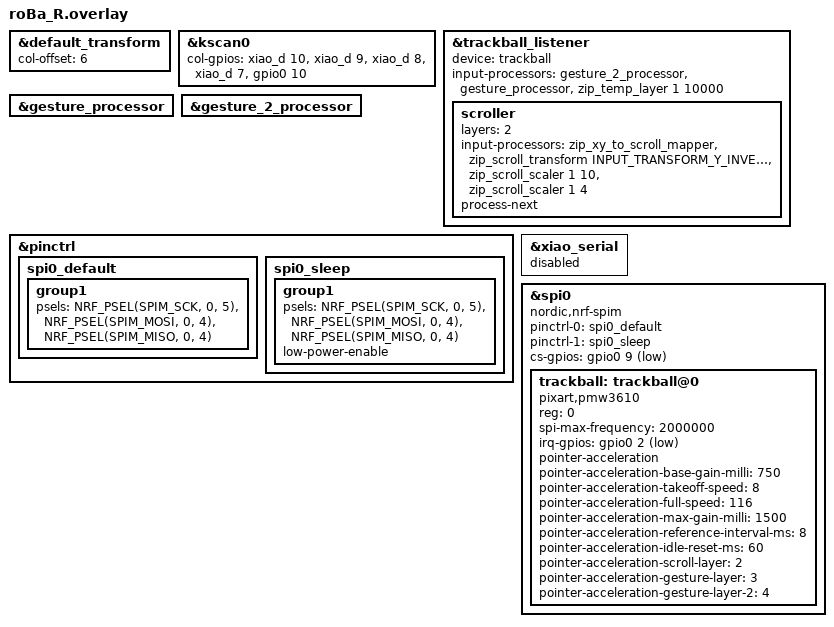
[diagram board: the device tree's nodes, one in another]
#include "roBa.dtsi"
#include <dt-bindings/zmk/input_transform.h>

&default_transform {
    col-offset = <6>;
};

&kscan0 {
        col-gpios
            = <&xiao_d 10 GPIO_ACTIVE_HIGH>
            , <&xiao_d 9 GPIO_ACTIVE_HIGH>
            , <&xiao_d 8 GPIO_ACTIVE_HIGH>
            , <&xiao_d 7 GPIO_ACTIVE_HIGH>
            , <&gpio0 10 GPIO_ACTIVE_HIGH>
            ;
};

&trackball_listener {
    status = "okay";
    device = <&trackball>;
    input-processors =
        <&gesture_2_processor>,
        <&gesture_processor>,
        <&zip_temp_layer 1 10000>;

    scroller {
        layers = <2>;
        input-processors =
            <&zip_xy_to_scroll_mapper>,
            <&zip_scroll_transform INPUT_TRANSFORM_Y_INVERT>,
            <&zip_scroll_scaler 1 10>,
            <&zip_scroll_scaler 1 4>;
        process-next;
    };
};

&gesture_processor {
    status = "okay";
};

&gesture_2_processor {
    status = "okay";
};

&pinctrl {
    spi0_default: spi0_default {
        group1 {
            psels = <NRF_PSEL(SPIM_SCK, 0, 5)>,
                <NRF_PSEL(SPIM_MOSI, 0, 4)>,
                <NRF_PSEL(SPIM_MISO, 0, 4)>;
        };
    };

    spi0_sleep: spi0_sleep {
        group1 {
            psels = <NRF_PSEL(SPIM_SCK, 0, 5)>,
                <NRF_PSEL(SPIM_MOSI, 0, 4)>,
                <NRF_PSEL(SPIM_MISO, 0, 4)>;
            low-power-enable;
        };
    };
};

&xiao_serial { status = "disabled"; };

&spi0 {
    status = "okay";
    compatible = "nordic,nrf-spim";
    pinctrl-0 = <&spi0_default>;
    pinctrl-1 = <&spi0_sleep>;
    pinctrl-names = "default", "sleep";
    cs-gpios = <&gpio0 9 GPIO_ACTIVE_LOW>;

    trackball: trackball@0 {
        status = "okay";
        compatible = "pixart,pmw3610";
        reg = <0>;
        spi-max-frequency = <2000000>;
        irq-gpios = <&gpio0 2 (GPIO_ACTIVE_LOW | GPIO_PULL_UP)>;
        /*
         * Use a 600-CPI-equivalent low-speed baseline: 800 CPI at 0.75x.
         * Thresholds account for roBa's 34 mm ball, 800 CPI, and 8 ms report
         * cadence. Acceleration begins where the former precision transition
         * began, while preserving the existing high-speed limit and without
         * replacing this driver's orientation, polling, or power path.
         */
        pointer-acceleration;
        pointer-acceleration-base-gain-milli = <750>;
        pointer-acceleration-takeoff-speed = <8>;
        pointer-acceleration-full-speed = <116>;
        pointer-acceleration-max-gain-milli = <1500>;
        pointer-acceleration-reference-interval-ms = <8>;
        pointer-acceleration-idle-reset-ms = <60>;
        pointer-acceleration-scroll-layer = <2>;
        pointer-acceleration-gesture-layer = <3>;
        pointer-acceleration-gesture-layer-2 = <4>;
    };
};
